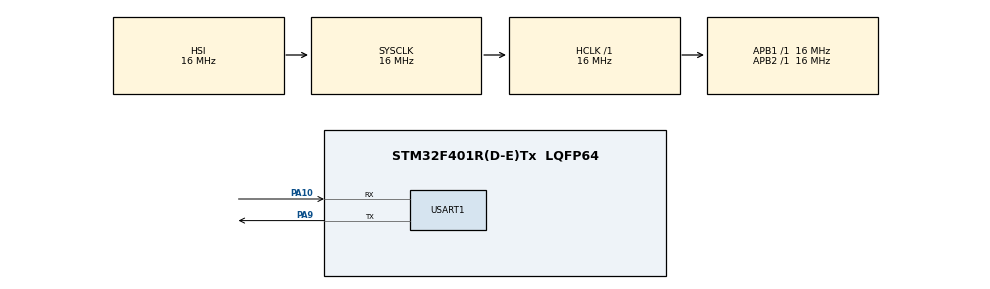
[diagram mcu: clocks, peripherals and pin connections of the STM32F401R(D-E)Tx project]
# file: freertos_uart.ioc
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FREERTOS.Tasks01=defaultTask,24,128,StartDefaultTask,Default,NULL,Dynamic,NULL,NULL
Mcu.Family=STM32F4
Mcu.Name=STM32F401R(D-E)Tx
Mcu.Package=LQFP64
NVIC.PriorityGroup=NVIC_PRIORITYGROUP_4
PA10.Mode=Asynchronous
PA10.Signal=USART1_RX
PA9.Mode=Asynchronous
PA9.Signal=USART1_TX
ProjectManager.HeapSize=0x200
ProjectManager.StackSize=0x400
ProjectManager.TargetToolchain=STM32CubeIDE
RCC.AHBFreq_Value=16000000
RCC.APB1Freq_Value=16000000
RCC.APB2Freq_Value=16000000
RCC.CortexFreq_Value=16000000
RCC.HSE_VALUE=25000000
RCC.HSI_VALUE=16000000
RCC.LSE_VALUE=32768
RCC.SYSCLKFreq_VALUE=16000000
RCC.VCOOutputFreq_Value=192000000
USART1.VirtualMode=VM_ASYNC
VP_FREERTOS_VS_CMSIS_V2.Mode=CMSIS_V2
board=custom

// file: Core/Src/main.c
/* USER CODE BEGIN Header */
/**
  ******************************************************************************
  * @file           : main.c
  * @brief          : Main program body
  ******************************************************************************
  * @attention
  *
  * Copyright (c) 2025 STMicroelectronics.
  * All rights reserved.
  *
  * This software is licensed under terms that can be found in the LICENSE file
  * in the root directory of this software component.
  * If no LICENSE file comes with this software, it is provided AS-IS.
  *
  ******************************************************************************
  */
/* USER CODE END Header */
#include "main.h"
#include "cmsis_os.h"

/* USER CODE BEGIN Includes */
#include <stdio.h>
#include <string.h>
#include "FreeRTOS.h"
#include "queue.h"

/* USER CODE END Includes */

/* USER CODE BEGIN PD */
#define QueueLength 64
/* USER CODE END PD */

UART_HandleTypeDef huart1;

/* Definitions for defaultTask */
osThreadId_t defaultTaskHandle;
const osThreadAttr_t defaultTask_attributes = {
  .name = "defaultTask",
  .stack_size = 128 * 4,
  .priority = (osPriority_t) osPriorityNormal,
};
/* USER CODE BEGIN PV */
QueueHandle_t uartQueue;
/* USER CODE END PV */

void SystemClock_Config(void);
static void MX_GPIO_Init(void);
static void MX_USART1_UART_Init(void);
void StartDefaultTask(void *argument);

/* USER CODE BEGIN PFP */
void StartUartSend(void * args);
void StartUartReceive(void * args);
/* USER CODE END PFP */

/* USER CODE BEGIN 0 */
uint8_t rx_char;
/* USER CODE END 0 */

int main(void)
{

  /* MCU Configuration--------------------------------------------------------*/

  /* Reset of all peripherals, Initializes the Flash interface and the Systick. */
  HAL_Init();

  /* Configure the system clock */
  SystemClock_Config();

  /* Initialize all configured peripherals */
  MX_GPIO_Init();
  MX_USART1_UART_Init();
  /* USER CODE BEGIN 2 */
  char hello[] = "UART Ready.\r\n";
  HAL_UART_Transmit(&huart1, (uint8_t*)hello, strlen(hello), 100); // init and testing message

  /* USER CODE END 2 */

  /* Init scheduler */
  osKernelInitialize();

  /* USER CODE BEGIN RTOS_QUEUES */
  uartQueue = xQueueCreate(QueueLength, sizeof(uint8_t));  // Create queue

  /* add queues, ... */
  /* USER CODE END RTOS_QUEUES */

  /* Create the thread(s) */
  /* creation of defaultTask */
  defaultTaskHandle = osThreadNew(StartDefaultTask, NULL, &defaultTask_attributes);

  /* USER CODE BEGIN RTOS_THREADS */
 // The creation of the two tasks one receive the uart message and the other one send back
  xTaskCreate(StartUartSend, "UART_TX", 256, NULL, 2, NULL);
  xTaskCreate(StartUartReceive, "UART_RX", 256, NULL, 2, NULL);

  /* add threads, ... */
  /* USER CODE END RTOS_THREADS */

  /* Start scheduler */
  osKernelStart();

  /* We should never get here as control is now taken by the scheduler */

  /* Infinite loop */
  while (1)
  {

  }
}

void SystemClock_Config(void)
{
  RCC_OscInitTypeDef RCC_OscInitStruct = {0};
  RCC_ClkInitTypeDef RCC_ClkInitStruct = {0};

  /** Configure the main internal regulator output voltage
  */
  __HAL_RCC_PWR_CLK_ENABLE();
  __HAL_PWR_VOLTAGESCALING_CONFIG(PWR_REGULATOR_VOLTAGE_SCALE2);

  /** Initializes the RCC Oscillators according to the specified parameters
  * in the RCC_OscInitTypeDef structure.
  */
  RCC_OscInitStruct.OscillatorType = RCC_OSCILLATORTYPE_HSI;
  RCC_OscInitStruct.HSIState = RCC_HSI_ON;
  RCC_OscInitStruct.HSICalibrationValue = RCC_HSICALIBRATION_DEFAULT;
  RCC_OscInitStruct.PLL.PLLState = RCC_PLL_NONE;
  if (HAL_RCC_OscConfig(&RCC_OscInitStruct) != HAL_OK)
  {
    Error_Handler();
  }

  /** Initializes the CPU, AHB and APB buses clocks
  */
  RCC_ClkInitStruct.ClockType = RCC_CLOCKTYPE_HCLK|RCC_CLOCKTYPE_SYSCLK
                              |RCC_CLOCKTYPE_PCLK1|RCC_CLOCKTYPE_PCLK2;
  RCC_ClkInitStruct.SYSCLKSource = RCC_SYSCLKSOURCE_HSI;
  RCC_ClkInitStruct.AHBCLKDivider = RCC_SYSCLK_DIV1;
  RCC_ClkInitStruct.APB1CLKDivider = RCC_HCLK_DIV1;
  RCC_ClkInitStruct.APB2CLKDivider = RCC_HCLK_DIV1;

  if (HAL_RCC_ClockConfig(&RCC_ClkInitStruct, FLASH_LATENCY_0) != HAL_OK)
  {
    Error_Handler();
  }
}

static void MX_USART1_UART_Init(void)
{

  huart1.Instance = USART1;
  huart1.Init.BaudRate = 115200;
  huart1.Init.WordLength = UART_WORDLENGTH_8B;
  huart1.Init.StopBits = UART_STOPBITS_1;
  huart1.Init.Parity = UART_PARITY_NONE;
  huart1.Init.Mode = UART_MODE_TX_RX;
  huart1.Init.HwFlowCtl = UART_HWCONTROL_NONE;
  huart1.Init.OverSampling = UART_OVERSAMPLING_16;
  if (HAL_UART_Init(&huart1) != HAL_OK)
  {
    Error_Handler();
  }

}

static void MX_GPIO_Init(void)
{

  /* GPIO Ports Clock Enable */
  __HAL_RCC_GPIOA_CLK_ENABLE();

}

/* USER CODE BEGIN 4 */

// the implementation of the two tasks
void StartUartReceive(void *args) {
    uint8_t rx_char;
    for (;;) {
        // Blocking receive 1 byte (wait forever)
        if (HAL_UART_Receive(&huart1, &rx_char, 1, HAL_MAX_DELAY) == HAL_OK) {
            // Send received byte to queue
            xQueueSend(uartQueue, &rx_char, portMAX_DELAY);

        }
    }
}

void StartUartSend(void* args) {
    uint8_t tx_char;
    char msg_buffer[128]; // buffer to store all chars until the presence of \r\n
    uint16_t index = 0;

    for(;;) {
        if (xQueueReceive(uartQueue, &tx_char, portMAX_DELAY) == pdPASS) { // check if uartQueue received something if yes put it in tx_char
            // Store char in buffer
            msg_buffer[index++] = tx_char;

            // Check for \r\n at the end
            if (index >= 2 &&
                msg_buffer[index-2] == '\r' &&
                msg_buffer[index-1] == '\n') {

                // Send entire message at once
                HAL_UART_Transmit(&huart1, (uint8_t*)msg_buffer, index, HAL_MAX_DELAY);

                // Reset buffer
                index = 0;
            }

        }
    }
}

/* USER CODE END 4 */

void StartDefaultTask(void *argument)
{
  for(;;)
  {
    osDelay(1);
  }
}

void Error_Handler(void)
{
  __disable_irq();
  while (1)
  {
  }
}
